# HK32F0301M register map
Vendor: HKMicroChip Ltd.; Series: HK32F0301M; File version: 1.0
CPU: CM0 r0p0, little endian, no MPU, no FPU, 3 interrupt priority bits
Registers are 32-bit, read-write, reset 0x0 unless marked. A register's access mark holds for its fields unless they carry their own. Offsets are from the block's base; [hi:lo] are bit positions.

## RCC — Reset and clock control
Base 0x40021000
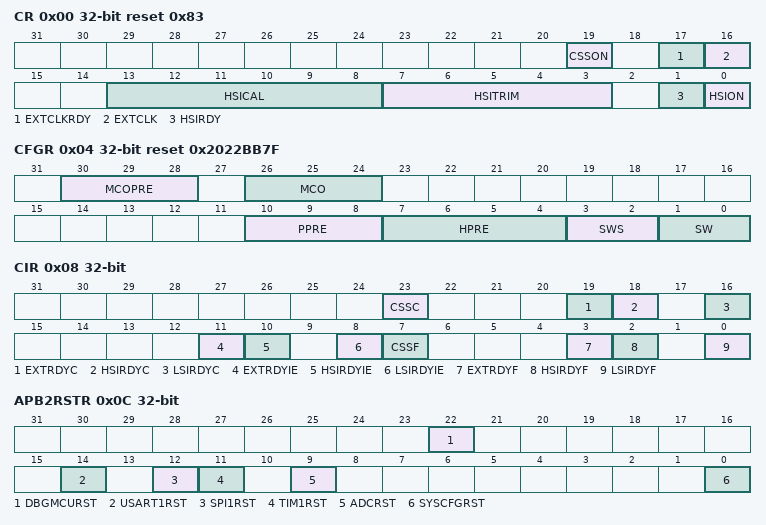
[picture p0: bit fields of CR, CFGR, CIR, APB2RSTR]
0x00 CR access per field reset 0x83 — Clock control register
  [19] CSSON rw — Clock Security System enable
  [17] EXTCLKRDY ro — External High Speed clock ready flag
  [16] EXTCLK rw — External High Speed clock enable
  [13:8] HSICAL rw — Internal High Speed clock Calibration
  [7:3] HSITRIM rw — Internal High Speed clock trimming
  [1] HSIRDY ro — Internal High Speed clock ready flag
  [0] HSION rw — Internal High Speed clock enable
0x04 CFGR access per field reset 0x2022BB7F — Clock configuration register (RCC_CFGR)
  [30:28] MCOPRE rw — Microcontroller Clock Output Prescaler
  [26:24] MCO rw — Microcontroller clock output
  [10:8] PPRE rw — APB Low speed prescaler (APB1)
  [7:4] HPRE rw — AHB prescaler
  [3:2] SWS ro — System Clock Switch Status
  [1:0] SW rw — System clock Switch
0x08 CIR access per field — Clock interrupt register (RCC_CIR)
  [23] CSSC wo — Clock security system interrupt clear
  [19] EXTRDYC wo — EXT Ready Interrupt Clear
  [18] HSIRDYC wo — HSI Ready Interrupt Clear
  [16] LSIRDYC wo — LSI Ready Interrupt Clear
  [11] EXTRDYIE rw — EXT Ready Interrupt Enable
  [10] HSIRDYIE rw — HSI Ready Interrupt Enable
  [8] LSIRDYIE rw — LSI Ready Interrupt Enable
  [7] CSSF ro — Clock Security System Interrupt flag
  [3] EXTRDYF ro — EXT Ready Interrupt flag
  [2] HSIRDYF ro — HSI Ready Interrupt flag
  [0] LSIRDYF ro — LSI Ready Interrupt flag
0x0C APB2RSTR — APB2 peripheral reset register (RCC_APB2RSTR)
  [22] DBGMCURST — Debug MCU reset
  [14] USART1RST — USART1 reset
  [12] SPI1RST — SPI 1 reset
  [11] TIM1RST — TIM1 timer reset
  [9] ADCRST — ADC interface reset
  [0] SYSCFGRST — SYSCFG and COMP reset
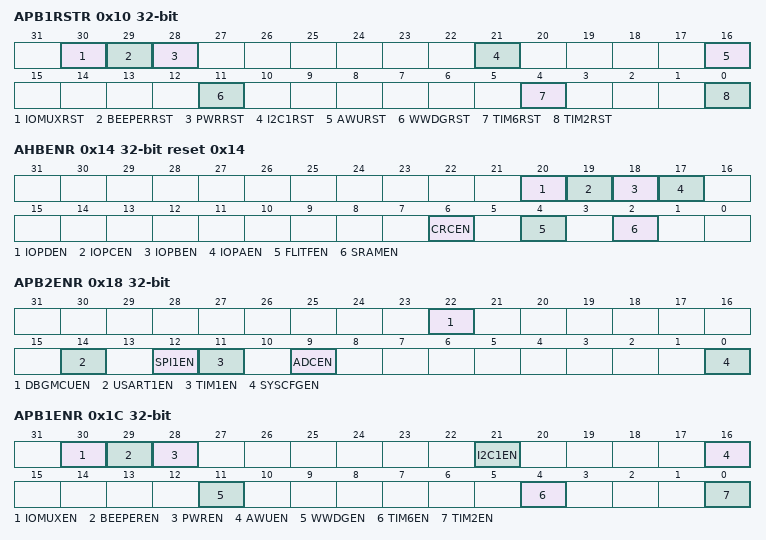
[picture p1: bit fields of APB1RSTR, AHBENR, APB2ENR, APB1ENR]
0x10 APB1RSTR — APB1 peripheral reset register (RCC_APB1RSTR)
  [30] IOMUXRST — IO MUX reset
  [29] BEEPERRST — beeper reset
  [28] PWRRST — Power interface reset
  [21] I2C1RST — I2C1 reset
  [16] AWURST — STOP wakeup
  [11] WWDGRST — Window watchdog reset
  [4] TIM6RST — Timer 6 reset
  [0] TIM2RST — Timer 2 reset
0x14 AHBENR reset 0x14 — AHB Peripheral Clock enable register (RCC_AHBENR)
  [20] IOPDEN — I/O port D clock enable
  [19] IOPCEN — I/O port C clock enable
  [18] IOPBEN — I/O port B clock enable
  [17] IOPAEN — I/O port A clock enable
  [6] CRCEN — CRC clock enable
  [4] FLITFEN — FLITF clock enable
  [2] SRAMEN — SRAM interface clock enable
0x18 APB2ENR — APB2 peripheral clock enable register (RCC_APB2ENR)
  [22] DBGMCUEN — MCU debug module clock enable
  [14] USART1EN — USART1 clock enable
  [12] SPI1EN — SPI 1 clock enable
  [11] TIM1EN — TIM1 Timer clock enable
  [9] ADCEN — ADC 1 interface clock enable
  [0] SYSCFGEN — SYSCFG clock enable
0x1C APB1ENR — APB1 peripheral clock enable register (RCC_APB1ENR)
  [30] IOMUXEN — IOMUX interface clock enable
  [29] BEEPEREN — beeper clock enable
  [28] PWREN — Power interface clock enable
  [21] I2C1EN — I2C 1 clock enable
  [16] AWUEN — stop wakeup enable
  [11] WWDGEN — Window watchdog clock enable
  [4] TIM6EN — Timer 6 clock enable
  [0] TIM2EN — Timer 2 clock enable
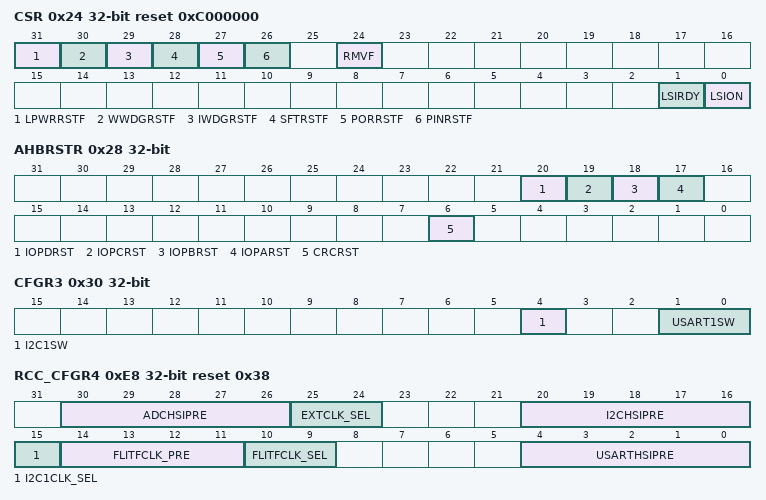
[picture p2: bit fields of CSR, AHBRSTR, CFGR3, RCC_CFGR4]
0x24 CSR access per field reset 0xC000000 — Control/status register (RCC_CSR)
  [31] LPWRRSTF rw — Low-power reset flag
  [30] WWDGRSTF rw — Window watchdog reset flag
  [29] IWDGRSTF rw — Independent watchdog reset flag
  [28] SFTRSTF rw — Software reset flag
  [27] PORRSTF rw — POR/PDR reset flag
  [26] PINRSTF rw — PIN reset flag
  [24] RMVF rw — Remove reset flag
  [1] LSIRDY ro — Internal low speed oscillator ready
  [0] LSION rw — Internal low speed oscillator enable
0x28 AHBRSTR — AHB peripheral reset register
  [20] IOPDRST — I/O port D reset
  [19] IOPCRST — I/O port C reset
  [18] IOPBRST — I/O port B reset
  [17] IOPARST — I/O port A reset
  [6] CRCRST — CRC reset
0x30 CFGR3 — Clock configuration register 3
  [4] I2C1SW — I2C1 clock source selection
  [1:0] USART1SW — USART1 clock source selection
0xE0 RCC_CSS reset 0x1E000000 — RCC control register
  [31:25] CSS_THRESHOLD — Control the threshold of the CSS counter
0xE8 RCC_CFGR4 reset 0x38 — Clock configuration register 4
  [30:26] ADCHSIPRE
  [25:24] EXTCLK_SEL — External clock input pin selection
  [20:16] I2CHSIPRE
  [15] I2C1CLK_SEL
  [14:11] FLITFCLK_PRE
  [10:9] FLITFCLK_SEL
  [4:0] USARTHSIPRE — USART Clock
